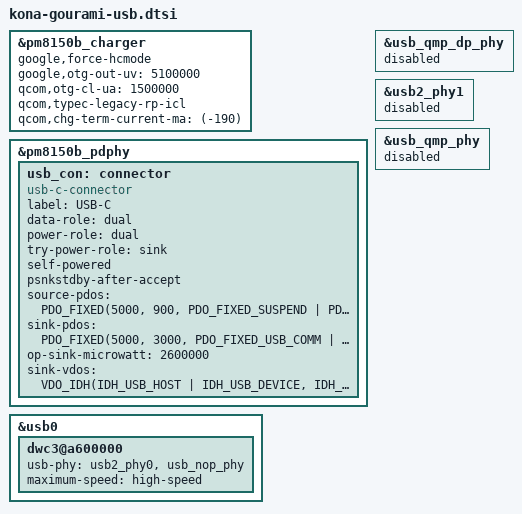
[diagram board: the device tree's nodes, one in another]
// SPDX-License-Identifier: GPL-2.0
/* Copyright (c) 2022, The Linux Foundation. All rights reserved.
 *
 * This program is free software; you can redistribute it and/or modify
 * it under the terms of the GNU General Public License version 2 and
 * only version 2 as published by the Free Software Foundation.
 *
 * This program is distributed in the hope that it will be useful,
 * but WITHOUT ANY WARRANTY; without even the implied warranty of
 * MERCHANTABILITY or FITNESS FOR A PARTICULAR PURPOSE.  See the
 * GNU General Public License for more details.
 */

#include <dt-bindings/usb/pd.h>

&pm8150b_charger {
	google,force-hcmode;
	google,otg-out-uv = <5100000>;
	qcom,otg-cl-ua = <1500000>;
	qcom,typec-legacy-rp-icl;
	qcom,chg-term-current-ma = <(-190)>;
};

&pm8150b_pdphy {
	usb_con: connector {
		compatible = "usb-c-connector";
		label = "USB-C";
		data-role = "dual";
		power-role = "dual";
		try-power-role = "sink";
		self-powered;
		psnkstdby-after-accept;
		source-pdos = <PDO_FIXED(5000, 900,
					 PDO_FIXED_SUSPEND
					 | PDO_FIXED_USB_COMM
					 | PDO_FIXED_DATA_SWAP
					 | PDO_FIXED_DUAL_ROLE)>;
		sink-pdos = <PDO_FIXED(5000, 3000, PDO_FIXED_USB_COMM
						   | PDO_FIXED_DATA_SWAP
						   | PDO_FIXED_DUAL_ROLE)
			     PDO_FIXED(9000, 2200, 0)
			     PDO_PPS_APDO(5000, 11000, 3000)>;
		op-sink-microwatt = <2600000>;
		sink-vdos = <VDO_IDH(IDH_USB_HOST | IDH_USB_DEVICE,
				     IDH_PTYPE_PERIPH,
				     IDH_PTYPE_HOST,
				     0x18D1)
			     VDO_CERT(0x0)
			     VDO_PRODUCT(0x4EE1, 0x0)>;
	};
};

&usb0 {
    dwc3@a600000 {
            usb-phy = <&usb2_phy0>, <&usb_nop_phy>;
            maximum-speed = "high-speed";
    };
};

&usb_qmp_dp_phy {
    status = "disabled";
};

&usb2_phy1 {
    status = "disabled";
};

&usb_qmp_phy {
    status = "disabled";
};
